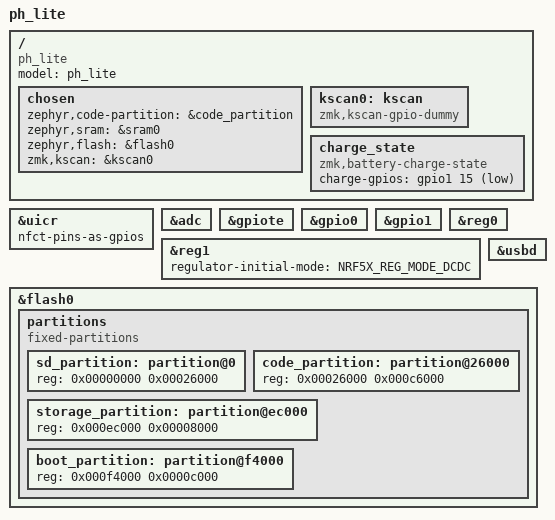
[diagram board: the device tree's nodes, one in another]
/*
 * Copyright (c) 2021 The ZMK Contributors
 *
 * SPDX-License-Identifier: MIT
 */

#include <nordic/nrf52840_qiaa.dtsi>
#include <zephyr/dt-bindings/regulator/nrf5x.h>
#include "ph_lite-pinctrl.dtsi"

/ {
    model = "ph_lite";
    compatible = "ph_lite";

    chosen {
        zephyr,code-partition = &code_partition;
        zephyr,sram = &sram0;
        zephyr,flash = &flash0;
        zmk,kscan = &kscan0;
    };

    kscan0: kscan {
        compatible = "zmk,kscan-gpio-dummy";
    };


    charge_state: charge_state {
        compatible = "zmk,battery-charge-state";
        charge-gpios = <&gpio1 15 GPIO_ACTIVE_LOW>;
    };
};

&uicr {
    nfct-pins-as-gpios;
};

&adc {
    status = "okay";
};

&gpiote {
    status = "okay";
};

&gpio0 {
    status = "okay";
};

&gpio1 {
    status = "okay";
};

&reg0 {
    status = "okay";
};

&reg1 {
    regulator-initial-mode = <NRF5X_REG_MODE_DCDC>;
};

zephyr_udc0: &usbd {
    status = "okay";
};


&flash0 {
    /*
     * For more information, see:
     * http://docs.zephyrproject.org/latest/devices/dts/flash_partitions.html
     */
    partitions {
        compatible = "fixed-partitions";
        #address-cells = <1>;
        #size-cells = <1>;

        sd_partition: partition@0 {
            reg = <0x00000000 0x00026000>;
        };
        code_partition: partition@26000 {
            reg = <0x00026000 0x000c6000>;
        };

        /*
         * The flash starting at 0x000ec000 and ending at
         * 0x000f3fff is reserved for use by the application.
         */

        /*
         * Storage partition will be used by FCB/LittleFS/NVS
         * if enabled.
         */
        storage_partition: partition@ec000 {
            reg = <0x000ec000 0x00008000>;
        };

        boot_partition: partition@f4000 {
            reg = <0x000f4000 0x0000c000>;
        };
    };
};
